# daric register map
Vendor: cramium
Registers are 32-bit, read-write, reset 0x0 unless marked. A register's access mark holds for its fields unless they carry their own. Offsets are from the block's base; [hi:lo] are bit positions.

## COMBOHASH
Base 0x4002B000
0x00 SFR_CRFUNC — See file:///F:/code/cram-soc/soc_oss/rtl/crypto/combohash_v0.3.sv
  [7:0] cr_func — cr_func read/write control register
0x04 SFR_AR — See file:///F:/code/cram-soc/soc_oss/rtl/crypto/combohash_v0.3.sv
  [31:0] sfr_ar — sfr_ar performs action on write of value: 0x5a
0x08 SFR_SRMFSM — See file:///F:/code/cram-soc/soc_oss/rtl/crypto/combohash_v0.3.sv
  [7:0] mfsm — mfsm read only status register
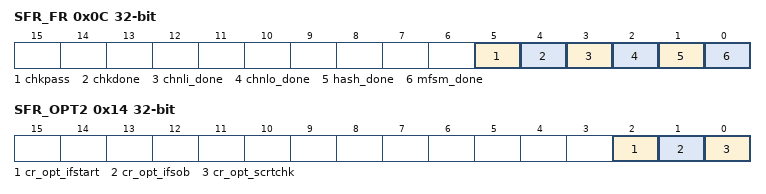
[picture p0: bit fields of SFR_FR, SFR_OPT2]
0x0C SFR_FR — See file:///F:/code/cram-soc/soc_oss/rtl/crypto/combohash_v0.3.sv
  [5] chkpass — chkpass flag register. `1` means event happened, write back `1` in respective bit position to clear the flag
  [4] chkdone — chkdone flag register. `1` means event happened, write back `1` in respective bit position to clear the flag
  [3] chnli_done — chnli_done flag register. `1` means event happened, write back `1` in respective bit position to clear the flag
  [2] chnlo_done — chnlo_done flag register. `1` means event happened, write back `1` in respective bit position to clear the flag
  [1] hash_done — hash_done flag register. `1` means event happened, write back `1` in respective bit position to clear the flag
  [0] mfsm_done — mfsm_done flag register. `1` means event happened, write back `1` in respective bit position to clear the flag
0x10 SFR_OPT1 — See file:///F:/code/cram-soc/soc_oss/rtl/crypto/combohash_v0.3.sv
  [15:0] cr_opt_hashcnt — cr_opt_hashcnt read/write control register
0x14 SFR_OPT2 — See file:///F:/code/cram-soc/soc_oss/rtl/crypto/combohash_v0.3.sv
  [2] cr_opt_ifstart — cr_opt.ifstart read/write control register
  [1] cr_opt_ifsob — cr_opt.ifsob read/write control register
  [0] cr_opt_scrtchk — cr_opt.scrtchk read/write control register
0x18 SFR_OPT3 — See file:///F:/code/cram-soc/soc_oss/rtl/crypto/combohash_v0.3.sv
  [7:0] sfr_opt3 — sfr_opt3 read/write control register
0x1C SFR_BLKT0 — See file:///F:/code/cram-soc/soc_oss/rtl/crypto/combohash_v0.3.sv
  [7:0] sfr_blkt0 — sfr_blkt0 read/write control register
0x20 SFR_SEGPTR_SEGID_LKEY — See file:///F:/code/cram-soc/soc_oss/rtl/crypto/combohash_v0.3.sv
  [11:0] SEGID_LKEY — cr_segptrstart read/write control register
0x24 SFR_SEGPTR_SEGID_KEY — See file:///F:/code/cram-soc/soc_oss/rtl/crypto/combohash_v0.3.sv
  [11:0] SEGID_KEY — cr_segptrstart read/write control register
0x2C SFR_SEGPTR_SEGID_SCRT — See file:///F:/code/cram-soc/soc_oss/rtl/crypto/combohash_v0.3.sv
  [11:0] SEGID_SCRT — cr_segptrstart read/write control register
0x30 SFR_SEGPTR_SEGID_MSG — See file:///F:/code/cram-soc/soc_oss/rtl/crypto/combohash_v0.3.sv
  [11:0] SEGID_MSG — cr_segptrstart read/write control register
0x34 SFR_SEGPTR_SEGID_HOUT — See file:///F:/code/cram-soc/soc_oss/rtl/crypto/combohash_v0.3.sv
  [11:0] SEGID_HOUT — cr_segptrstart read/write control register
0x3C SFR_SEGPTR_SEGID_HOUT2 — See file:///F:/code/cram-soc/soc_oss/rtl/crypto/combohash_v0.3.sv
  [11:0] SEGID_HOUT2 — cr_segptrstart read/write control register

## PKE
Base 0x4002C000
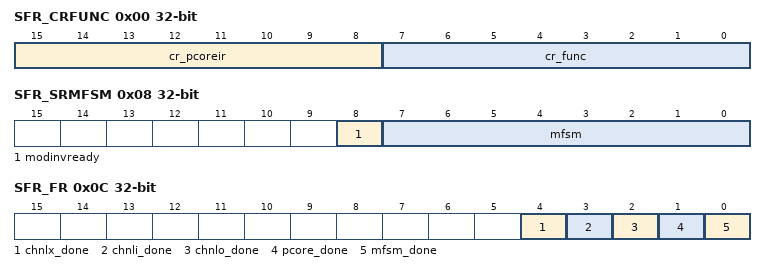
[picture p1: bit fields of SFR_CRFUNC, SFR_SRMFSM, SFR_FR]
0x00 SFR_CRFUNC — See file:///F:/code/cram-soc/soc_oss/rtl/crypto/pke_v0.3tmp.sv
  [15:8] cr_pcoreir — cr_pcoreir read/write control register
  [7:0] cr_func — cr_func read/write control register
0x04 SFR_AR — See file:///F:/code/cram-soc/soc_oss/rtl/crypto/pke_v0.3tmp.sv
  [31:0] sfr_ar — sfr_ar performs action on write of value: 0x5a
0x08 SFR_SRMFSM — See file:///F:/code/cram-soc/soc_oss/rtl/crypto/pke_v0.3tmp.sv
  [8] modinvready — modinvready read only status register
  [7:0] mfsm — mfsm read only status register
0x0C SFR_FR — See file:///F:/code/cram-soc/soc_oss/rtl/crypto/pke_v0.3tmp.sv
  [4] chnlx_done — chnlx_done flag register. `1` means event happened, write back `1` in respective bit position to clear the flag
  [3] chnli_done — chnli_done flag register. `1` means event happened, write back `1` in respective bit position to clear the flag
  [2] chnlo_done — chnlo_done flag register. `1` means event happened, write back `1` in respective bit position to clear the flag
  [1] pcore_done — pcore_done flag register. `1` means event happened, write back `1` in respective bit position to clear the flag
  [0] mfsm_done — mfsm_done flag register. `1` means event happened, write back `1` in respective bit position to clear the flag
0x10 SFR_OPTNW — See file:///F:/code/cram-soc/soc_oss/rtl/crypto/pke_v0.3tmp.sv
  [12:0] sfr_optnw — sfr_optnw read/write control register
0x14 SFR_OPTEW — See file:///F:/code/cram-soc/soc_oss/rtl/crypto/pke_v0.3tmp.sv
  [12:0] sfr_optew — sfr_optew read/write control register
0x18 SFR_OPTRW — See file:///F:/code/cram-soc/soc_oss/rtl/crypto/pke_v0.3tmp.sv
  [9:0] sfr_optrw — sfr_optrw read/write control register
0x1C SFR_OPTLTX — See file:///F:/code/cram-soc/soc_oss/rtl/crypto/pke_v0.3tmp.sv
  [4:0] sfr_optltx — sfr_optltx read/write control register
0x20 SFR_OPTMASK — See file:///F:/code/cram-soc/soc_oss/rtl/crypto/pke_v0.3tmp.sv
  [15:0] sfr_optmask — sfr_optmask read/write control register
0x30 SFR_SEGPTR_PTRID_PCON — See file:///F:/code/cram-soc/soc_oss/rtl/crypto/pke_v0.3tmp.sv
  [11:0] PTRID_PCON — cr_segptrstart read/write control register
0x34 SFR_SEGPTR_PTRID_PIB0 — See file:///F:/code/cram-soc/soc_oss/rtl/crypto/pke_v0.3tmp.sv
  [11:0] PTRID_PIB0 — cr_segptrstart read/write control register
0x38 SFR_SEGPTR_PTRID_PIB1 — See file:///F:/code/cram-soc/soc_oss/rtl/crypto/pke_v0.3tmp.sv
  [11:0] PTRID_PIB1 — cr_segptrstart read/write control register
0x3C SFR_SEGPTR_PTRID_PKB — See file:///F:/code/cram-soc/soc_oss/rtl/crypto/pke_v0.3tmp.sv
  [11:0] PTRID_PKB — cr_segptrstart read/write control register
0x40 SFR_SEGPTR_PTRID_POB — See file:///F:/code/cram-soc/soc_oss/rtl/crypto/pke_v0.3tmp.sv
  [11:0] PTRID_POB — cr_segptrstart read/write control register
